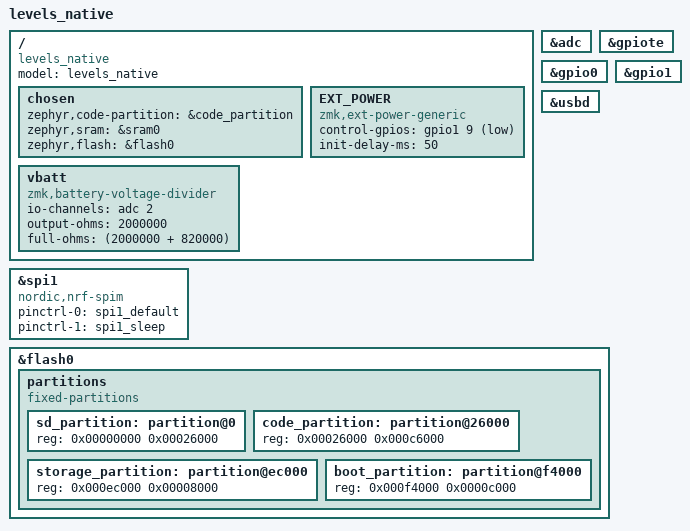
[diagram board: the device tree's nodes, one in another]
/dts-v1/;
#include <nordic/nrf52840_qiaa.dtsi>
#include "levels_native-pinctrl.dtsi"

/ {
  model = "levels_native";
  compatible = "levels_native";

  chosen {
		zephyr,code-partition = &code_partition;
		zephyr,sram = &sram0;
		zephyr,flash = &flash0;
  };
  // Node name must match original "EXT_POWER" label to preserve user settings.
  EXT_POWER {
    compatible = "zmk,ext-power-generic";
    control-gpios = <&gpio1 9 GPIO_ACTIVE_LOW>;
    init-delay-ms = <50>;
  };

  vbatt: vbatt {
    compatible = "zmk,battery-voltage-divider";
    io-channels = <&adc 2>;
    output-ohms = <2000000>;
    full-ohms = <(2000000 + 820000)>;
  };
};

&adc {
	status = "okay";
};

&gpiote {
    status = "okay";
};

&gpio0 {
	status = "okay";
};

&gpio1 {
	status = "okay";
};

&usbd {
	status = "okay";
};

&spi1 {
    compatible = "nordic,nrf-spim";
    pinctrl-0 = <&spi1_default>;
    pinctrl-1 = <&spi1_sleep>;
    pinctrl-names = "default", "sleep";
};

zephyr_udc0: &usbd {
    status = "okay";
};

&flash0 {
	/*
	 * For more information, see:
	 * http://docs.zephyrproject.org/latest/devices/dts/flash_partitions.html
	 */
  partitions {
    compatible = "fixed-partitions";
    #address-cells = <1>;
		#size-cells = <1>;

    sd_partition: partition@0 {
      reg = <0x00000000 0x00026000>;
    };
    code_partition: partition@26000 {
      reg = <0x00026000 0x000c6000>;
    };

    /*
     * The flash starting at 0x000ec000 and ending at
     * 0x000f3fff is reserved for use by the application.
     */

    /*
     * Storage partition will be used by FCB/LittleFS/NVS
     * if enabled.
     */
		storage_partition: partition@ec000 {
			reg = <0x000ec000 0x00008000>;
		};

		boot_partition: partition@f4000 {
			reg = <0x000f4000 0x0000c000>;
		};
  };
};
